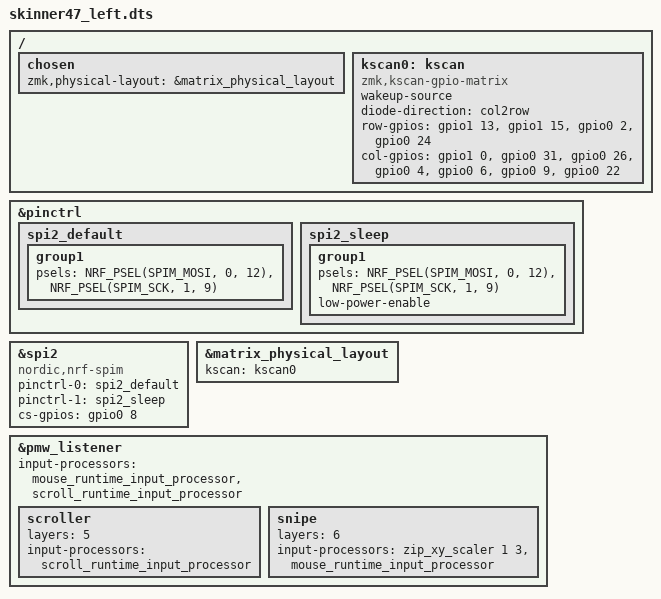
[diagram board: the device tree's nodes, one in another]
#include "skinner47.dtsi"
#include <dt-bindings/led/led.h>
#include <input/processors.dtsi>

&pinctrl {
    spi2_default: spi2_default {
				group1 {
						psels = <NRF_PSEL(SPIM_MOSI, 0, 12)>,
						<NRF_PSEL(SPIM_SCK, 1, 9)>;
				};
		};
	
    spi2_sleep: spi2_sleep {
				group1 {
						psels = <NRF_PSEL(SPIM_MOSI, 0, 12)>,
						<NRF_PSEL(SPIM_SCK, 1, 9)>;
						low-power-enable;
				};
		};
};


lpm_view_spi: &spi2 {
    compatible = "nordic,nrf-spim";
    pinctrl-0 = <&spi2_default>;
    pinctrl-1 = <&spi2_sleep>;
    pinctrl-names = "default", "sleep";
    cs-gpios = <&gpio0 8 (GPIO_ACTIVE_HIGH | GPIO_PULL_DOWN) >;
};

nice_view_spi: &spi2 {
    compatible = "nordic,nrf-spim";
    pinctrl-0 = <&spi2_default>;
    pinctrl-1 = <&spi2_sleep>;
    pinctrl-names = "default", "sleep";
    cs-gpios = <&gpio0 8 (GPIO_ACTIVE_HIGH | GPIO_PULL_DOWN) >;
};



&matrix_physical_layout {
  	kscan = <&kscan0>;
};

/ {
	chosen {
		zmk,physical-layout = &matrix_physical_layout;
	};
    kscan0: kscan {
        compatible = "zmk,kscan-gpio-matrix";
        wakeup-source;

        diode-direction = "col2row";
        row-gpios
            = <&gpio1 13 (GPIO_ACTIVE_HIGH | GPIO_PULL_DOWN)>
            , <&gpio1 15 (GPIO_ACTIVE_HIGH | GPIO_PULL_DOWN)>
            , <&gpio0 2 (GPIO_ACTIVE_HIGH | GPIO_PULL_DOWN)>
            , <&gpio0 24 (GPIO_ACTIVE_HIGH | GPIO_PULL_DOWN)>
            ;

			col-gpios
							= <&gpio1 0 (GPIO_ACTIVE_HIGH | GPIO_PULL_DOWN)>
							, <&gpio0 31 (GPIO_ACTIVE_HIGH | GPIO_PULL_DOWN)>
							, <&gpio0 26 (GPIO_ACTIVE_HIGH | GPIO_PULL_DOWN)>
							, <&gpio0 4 (GPIO_ACTIVE_HIGH | GPIO_PULL_DOWN)>
							, <&gpio0 6 (GPIO_ACTIVE_HIGH | GPIO_PULL_DOWN)>
							, <&gpio0 9 (GPIO_ACTIVE_HIGH | GPIO_PULL_DOWN)>
							, <&gpio0 22  (GPIO_ACTIVE_HIGH | GPIO_PULL_DOWN)>;
    };
};


&pmw_listener {
	status = "okay";

	// Trackball events arrive from the right (peripheral) half over the split
	// link. These runtime input processors are the ones DYA Studio configures
	// (speed, rotation, axis snap, ...).
	input-processors = <&mouse_runtime_input_processor &scroll_runtime_input_processor>;

	// when the scroll layer is active, the trackball will act as a mouse wheel
	scroller {
		layers = <5>;
		input-processors = <&scroll_runtime_input_processor>;
	};
	// when the snipe layer is active, the trackball will move more slowly
	snipe {
		layers =<6>;
		input-processors = <&zip_xy_scaler 1 3 &mouse_runtime_input_processor>;
	};
};
